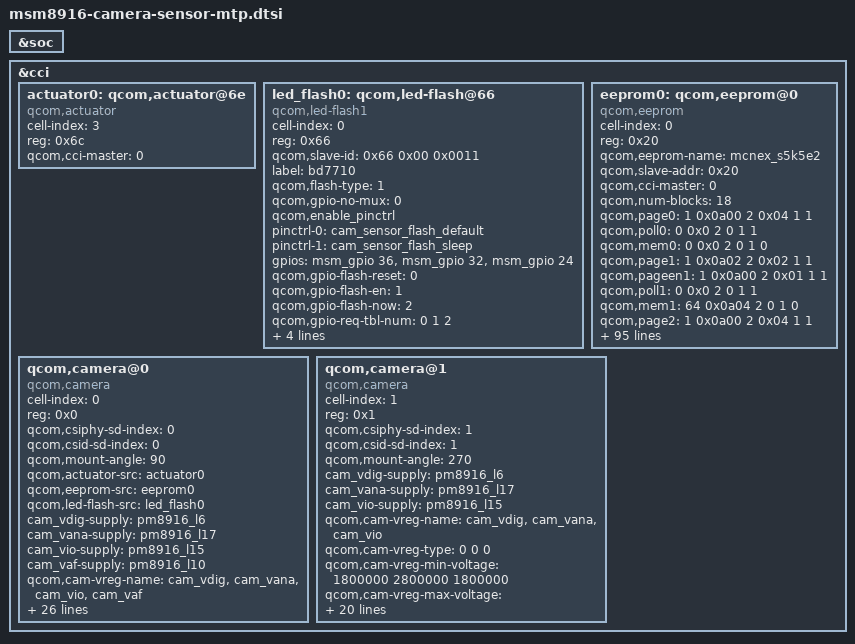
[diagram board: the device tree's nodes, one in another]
/*
 * Copyright (c) 2014, The Linux Foundation. All rights reserved.
 *
 * This program is free software; you can redistribute it and/or modify
 * it under the terms of the GNU General Public License version 2 and
 * only version 2 as published by the Free Software Foundation.
 *
 * This program is distributed in the hope that it will be useful,
 * but WITHOUT ANY WARRANTY; without even the implied warranty of
 * MERCHANTABILITY or FITNESS FOR A PARTICULAR PURPOSE.  See the
 * GNU General Public License for more details.
 */
/*
 * This software is contributed or developed by KYOCERA Corporation.
 * (C) 2015 KYOCERA Corporation
 */

&soc {
};

&cci {

	actuator0: qcom,actuator@6e {
		cell-index = <3>;
		reg = <0x6c>;
		compatible = "qcom,actuator";
		qcom,cci-master = <0>;
	};
	led_flash0: qcom,led-flash@66 {
		cell-index = <0>;
		reg = <0x66>;
		qcom,slave-id = <0x66 0x00 0x0011>;
		compatible = "qcom,led-flash1";
		label = "bd7710";
		qcom,flash-type = <1>;
		qcom,gpio-no-mux = <0>;
		qcom,enable_pinctrl;
		pinctrl-names = "cam_flash_default", "cam_flash_suspend";
		pinctrl-0 = <&cam_sensor_flash_default>;
		pinctrl-1 = <&cam_sensor_flash_sleep>;
		gpios = <&msm_gpio 36 0>,
			<&msm_gpio 32 0>,
			<&msm_gpio 24 0>;
		qcom,gpio-flash-reset = <0>;
		qcom,gpio-flash-en = <1>;
		qcom,gpio-flash-now = <2>;
		qcom,gpio-req-tbl-num = <0 1 2>;
		qcom,gpio-req-tbl-flags = <0 0 0>;
		qcom,gpio-req-tbl-label = "FLASH_RST",
			"FLASH_EN",
			"FLASH_NOW";
		qcom,cci-master = <0>;
	};

	eeprom0: qcom,eeprom@0{
		cell-index = <0>;
		reg = <0x20>;
		qcom,eeprom-name = "mcnex_s5k5e2";
		compatible = "qcom,eeprom";
		qcom,slave-addr = <0x20>;
		qcom,cci-master = <0>;
		qcom,num-blocks = <18>;
		qcom,page0 = <1 0x0a00 2 0x04 1 1>;
		qcom,poll0 = <0 0x0 2 0 1 1>;
		qcom,mem0 = <0 0x0 2 0 1 0>;
		qcom,page1 = <1 0x0a02 2 0x02 1 1>;
		qcom,pageen1 = <1 0x0a00 2 0x01 1 1>;
		qcom,poll1 = <0 0x0 2 0 1 1>;
                qcom,mem1 = <64 0x0a04 2 0 1 0>;
		qcom,page2 = <1 0x0a00 2 0x04 1 1>;
		qcom,poll2 = <0 0x0 2 0 1 1>;
		qcom,mem2 = <0 0x0 2 0 1 0>;
		qcom,page3 = <1 0x0a02 2 0x03 1 1>;
		qcom,pageen3 = <1 0x0a00 2 0x01 1 1>;
		qcom,poll3 = <0 0x0 2 0 1 1>;
                qcom,mem3 = <64 0x0a04 2 0 1 0>;
		qcom,page4 = <1 0x0a00 2 0x04 1 1>;
		qcom,poll4 = <0 0x0 2 0 1 1>;
		qcom,mem4 = <0 0x0 2 0 1 0>;
		qcom,page5 = <1 0x0a02 2 0x09 1 1>;
		qcom,pageen5 = <1 0x0a00 2 0x01 1 1>;
		qcom,poll5 = <0 0x0 2 0 1 1>;
                qcom,mem5 = <64 0x0a04 2 0 1 0>;
		qcom,page6 = <1 0x0a00 2 0x04 1 1>;
		qcom,poll6 = <0 0x0 2 0 1 1>;
		qcom,mem6 = <0 0x0 2 0 1 0>;
		qcom,page7 = <1 0x0a02 2 0x0a 1 1>;
		qcom,pageen7 = <1 0x0a00 2 0x01 1 1>;
		qcom,poll7 = <0 0x0 2 0 1 1>;
                qcom,mem7 = <64 0x0a04 2 0 1 0>;
		qcom,page8 = <1 0x0a00 2 0x04 1 1>;
		qcom,poll8 = <0 0x0 2 0 1 1>;
		qcom,mem8 = <0 0x0 2 0 1 0>;
		qcom,page9 = <1 0x0a02 2 0x0b 1 1>;
		qcom,pageen9 = <1 0x0a00 2 0x01 1 1>;
		qcom,poll9 = <0 0x0 2 0 1 1>;
                qcom,mem9 = <64 0x0a04 2 0 1 0>;
		qcom,page10 = <1 0x0a00 2 0x04 1 1>;
		qcom,poll10 = <0 0x0 2 0 1 1>;
		qcom,mem10 = <0 0x0 2 0 1 0>;
		qcom,page11 = <1 0x0a02 2 0x0c 1 1>;
		qcom,pageen11 = <1 0x0a00 2 0x01 1 1>;
		qcom,poll11 = <0 0x0 2 0 1 1>;
                qcom,mem11 = <64 0x0a04 2 0 1 0>;
		qcom,page12 = <1 0x0a00 2 0x04 1 1>;
		qcom,poll12 = <0 0x0 2 0 1 1>;
		qcom,mem12 = <0 0x0 2 0 1 0>;
		qcom,page13 = <1 0x0a02 2 0x0d 1 1>;
		qcom,pageen13 = <1 0x0a00 2 0x01 1 1>;
		qcom,poll13 = <0 0x0 2 0 1 1>;
                qcom,mem13 = <64 0x0a04 2 0 1 0>;
		qcom,page14 = <1 0x0a00 2 0x04 1 1>;
		qcom,poll14 = <0 0x0 2 0 1 1>;
		qcom,mem14 = <0 0x0 2 0 1 0>;
		qcom,page15 = <1 0x0a02 2 0x0e 1 1>;
		qcom,pageen15 = <1 0x0a00 2 0x01 1 1>;
		qcom,poll15 = <0 0x0 2 0 1 1>;
                qcom,mem15 = <64 0x0a04 2 0 1 0>;
		qcom,page16 = <1 0x0a00 2 0x04 1 1>;
		qcom,poll16 = <0 0x0 2 0 1 1>;
		qcom,mem16 = <0 0x0 2 0 1 0>;
		qcom,page17 = <1 0x0a02 2 0x0e 1 1>;
		qcom,pageen17 = <1 0x0a00 2 0x01 1 1>;
		qcom,poll17 = <0 0x0 2 0 1 1>;
                qcom,mem17 = <64 0x0a04 2 0 1 0>;

		cam_vdig-supply = <&pm8916_l6>;
		cam_vana-supply = <&pm8916_l17>;
		cam_vio-supply = <&pm8916_l15>;
		cam_vaf-supply = <&pm8916_l10>;
		qcom,cam-vreg-name = "cam_vdig", "cam_vana", "cam_vio", "cam_vaf";
		qcom,cam-vreg-type = <0 0 0 0>;
		qcom,cam-vreg-min-voltage = <1800000 2800000 1800000 2800000>;
		qcom,cam-vreg-max-voltage = <1800000 2800000 1800000 2800000>;
		qcom,cam-vreg-op-mode = <30000 30000 30000 30000>;
		qcom,cam-vreg-op-mode-idle = <100 100 100 100>;
		qcom,gpio-no-mux = <0>;
		pinctrl-names = "cam_default", "cam_suspend";
		pinctrl-0 = <&cam_sensor_mclk0_default &cam_sensor_rear_default>;
		pinctrl-1 = <&cam_sensor_mclk0_sleep &cam_sensor_rear_sleep>;
		gpios = <&msm_gpio 26 0>,
			<&msm_gpio 35 0>,
			<&msm_gpio 114 0>,
			<&msm_gpio 110 0>;
		qcom,gpio-reset = <1>;
		qcom,gpio-vdig = <2>;
		qcom,gpio-cam-main-id = <3>;
		qcom,gpio-req-tbl-num = <0 1 2 3>;
		qcom,gpio-req-tbl-flags = <0 0 0 1>;
		qcom,gpio-req-tbl-label = "CAMIF_MCLK",
			"CAM_RESET1",
			"CAM_VDIG",
			"CAM_MAIN_ID";
		qcom,cam-power-seq-type = "sensor_vreg","sensor_vreg","sensor_vreg",
                        "sensor_gpio", "sensor_gpio",
                        "sensor_vreg","sensor_gpio",
                        "sensor_gpio","sensor_clk";
		qcom,cam-power-seq-val =  "cam_vdig","cam_vana","cam_vio",
                        "sensor_gpio_vdig","sensor_gpio_vdig",
                        "cam_vaf","sensor_gpio_reset",
                        "sensor_gpio_reset","sensor_cam_mclk";
		qcom,cam-power-seq-cfg-val = <1 1 0 1 1 1 0 1 26022000>;
		qcom,cam-power-seq-delay = <5 1 1 1 1 1 1 1 10>;
		clocks = <&clock_gcc clk_mclk0_clk_src>,
				<&clock_gcc clk_gcc_camss_mclk0_clk>;
		clock-names = "cam_src_clk", "cam_clk";
	};

	qcom,camera@0 {
		cell-index = <0>;
		compatible = "qcom,camera";
		reg = <0x0>;
		qcom,csiphy-sd-index = <0>;
		qcom,csid-sd-index = <0>;
		qcom,mount-angle = <90>;
		qcom,actuator-src = <&actuator0>;
		qcom,eeprom-src = <&eeprom0>;
		qcom,led-flash-src = <&led_flash0>;
		cam_vdig-supply = <&pm8916_l6>;
		cam_vana-supply = <&pm8916_l17>;
		cam_vio-supply = <&pm8916_l15>;
		cam_vaf-supply = <&pm8916_l10>;
		qcom,cam-vreg-name = "cam_vdig", "cam_vana", "cam_vio", "cam_vaf";
		qcom,cam-vreg-type = <0 0 0 0>;
		qcom,cam-vreg-min-voltage = <1800000 2800000 1800000 2800000>;
		qcom,cam-vreg-max-voltage = <1800000 2800000 1800000 2800000>;
		qcom,cam-vreg-op-mode = <30000 30000 30000 30000>;
		qcom,cam-vreg-op-mode-idle = <100 100 100 100>;
		qcom,gpio-no-mux = <0>;
		pinctrl-names = "cam_default", "cam_suspend";
		pinctrl-0 = <&cam_sensor_mclk0_default &cam_sensor_rear_default &cam_main_id_active>;
		pinctrl-1 = <&cam_sensor_mclk0_sleep &cam_sensor_rear_sleep &cam_main_id_suspend>;
		gpios = <&msm_gpio 26 0>,
			<&msm_gpio 35 0>,
			<&msm_gpio 114 0>,
			<&msm_gpio 110 0>;
		qcom,gpio-reset = <1>;
		qcom,gpio-vdig = <2>;//tentative
		qcom,gpio-cam-main-id = <3>;
		qcom,gpio-req-tbl-num = <0 1 2 3>;
		qcom,gpio-req-tbl-flags = <0 0 0 1>;
		qcom,gpio-req-tbl-label = "CAMIF_MCLK",
			"CAM_RESET1",
			"CAM_VDIG",
			"CAM_MAIN_ID";
		qcom,sensor-position = <0>;
		qcom,sensor-mode = <0>;
		qcom,cci-master = <0>;
		status = "ok";
		clocks = <&clock_gcc clk_mclk0_clk_src>,
				<&clock_gcc clk_gcc_camss_mclk0_clk>;
		clock-names = "cam_src_clk", "cam_clk";
	};

	qcom,camera@1 {
		cell-index = <1>;
		compatible = "qcom,camera";
		reg = <0x1>;
		qcom,csiphy-sd-index = <1>;
		qcom,csid-sd-index = <1>;
		qcom,mount-angle = <270>;
		cam_vdig-supply = <&pm8916_l6>;
		cam_vana-supply = <&pm8916_l17>;
		cam_vio-supply = <&pm8916_l15>;
		qcom,cam-vreg-name = "cam_vdig", "cam_vana", "cam_vio";
		qcom,cam-vreg-type = <0 0 0>;
		qcom,cam-vreg-min-voltage = <1800000 2800000 1800000>;
		qcom,cam-vreg-max-voltage = <1800000 2800000 1800000>;
		qcom,cam-vreg-op-mode = <30000 30000 30000>;
		qcom,cam-vreg-op-mode-idle = <100 100 100>;
		qcom,gpio-no-mux = <0>;
		pinctrl-names = "cam_default", "cam_suspend";
		pinctrl-0 = <&cam_sensor_mclk1_default &cam_sensor_front_default &cam_sub_id_active>;
		pinctrl-1 = <&cam_sensor_mclk1_sleep &cam_sensor_front_sleep &cam_sub_id_suspend>;
		gpios = <&msm_gpio 27 0>,
			<&msm_gpio 28 0>,
			<&msm_gpio 117 0>;
		qcom,gpio-reset = <1>;
		qcom,gpio-cam-sub-id = <2>;
		qcom,gpio-req-tbl-num = <0 1 2>;
		qcom,gpio-req-tbl-flags = <0 0 1>;
		qcom,gpio-req-tbl-label = "CAMIF_MCLK",
			"CAM_RESET1",
			"CAM_SUB_ID";
		qcom,sensor-position = <1>;
		qcom,sensor-mode = <1>;
		qcom,cci-master = <0>;
		status = "ok";
		clocks = <&clock_gcc clk_mclk1_clk_src>,
				<&clock_gcc clk_gcc_camss_mclk1_clk>;
		clock-names = "cam_src_clk", "cam_clk";
	};

};
